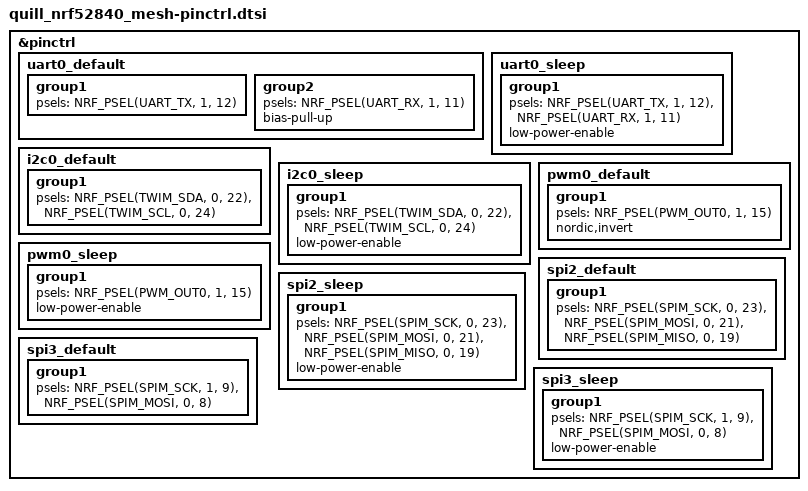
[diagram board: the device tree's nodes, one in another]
/*
 * Copyright (c) 2025 Chiho Sin
 *
 * SPDX-License-Identifier: Apache-2.0
 */

&pinctrl {
	uart0_default: uart0_default {
		group1 {
			psels = <NRF_PSEL(UART_TX, 1, 12)>;
		};

		group2 {
			psels = <NRF_PSEL(UART_RX, 1, 11)>;
			bias-pull-up;
		};
	};

	uart0_sleep: uart0_sleep {
		group1 {
			psels = <NRF_PSEL(UART_TX, 1, 12)>,
				<NRF_PSEL(UART_RX, 1, 11)>;
			low-power-enable;
		};
	};

	i2c0_default: i2c0_default {
		group1 {
			psels = <NRF_PSEL(TWIM_SDA, 0, 22)>,
				<NRF_PSEL(TWIM_SCL, 0, 24)>;
		};
	};

	i2c0_sleep: i2c0_sleep {
		group1 {
			psels = <NRF_PSEL(TWIM_SDA, 0, 22)>,
				<NRF_PSEL(TWIM_SCL, 0, 24)>;
			low-power-enable;
		};
	};

	pwm0_default: pwm0_default {
		group1 {
			psels = <NRF_PSEL(PWM_OUT0, 1, 15)>;
			nordic,invert;
		};
	};

	pwm0_sleep: pwm0_sleep {
		group1 {
			psels = <NRF_PSEL(PWM_OUT0, 1, 15)>;
			low-power-enable;
		};
	};

	spi2_default: spi2_default {
		group1 {
			psels = <NRF_PSEL(SPIM_SCK, 0, 23)>,
				<NRF_PSEL(SPIM_MOSI, 0, 21)>,
				<NRF_PSEL(SPIM_MISO, 0, 19)>;
		};
	};

	spi2_sleep: spi2_sleep {
		group1 {
			psels = <NRF_PSEL(SPIM_SCK, 0, 23)>,
				<NRF_PSEL(SPIM_MOSI, 0, 21)>,
				<NRF_PSEL(SPIM_MISO, 0, 19)>;
			low-power-enable;
		};
	};

	spi3_default: spi3_default {
		group1 {
			psels = <NRF_PSEL(SPIM_SCK, 1, 9)>,
				<NRF_PSEL(SPIM_MOSI, 0, 8)>;
		};
	};

	spi3_sleep: spi3_sleep {
		group1 {
			psels = <NRF_PSEL(SPIM_SCK, 1, 9)>,
				<NRF_PSEL(SPIM_MOSI, 0, 8)>;
			low-power-enable;
		};
	};
};
